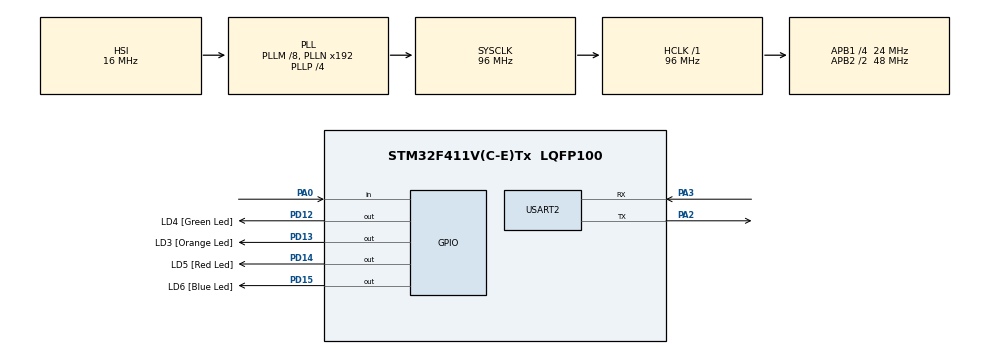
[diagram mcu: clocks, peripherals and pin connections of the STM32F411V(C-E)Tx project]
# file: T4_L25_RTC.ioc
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Mcu.Family=STM32F4
Mcu.Name=STM32F411V(C-E)Tx
Mcu.Package=LQFP100
NVIC.PriorityGroup=NVIC_PRIORITYGROUP_0
PA0-WKUP.Signal=GPIO_Input
PA2.Mode=Asynchronous
PA2.Signal=USART2_TX
PA3.Mode=Asynchronous
PA3.Signal=USART2_RX
PC14-OSC32_IN.Mode=LSE-External-Oscillator
PC14-OSC32_IN.Signal=RCC_OSC32_IN
PC15-OSC32_OUT.Mode=LSE-External-Oscillator
PC15-OSC32_OUT.Signal=RCC_OSC32_OUT
PD12.GPIO_Label=LD4 [Green Led]
PD12.GPIO_PuPd=GPIO_NOPULL
PD12.GPIO_Speed=GPIO_SPEED_FREQ_LOW
PD12.Signal=GPIO_Output
PD13.GPIO_Label=LD3 [Orange Led]
PD13.GPIO_PuPd=GPIO_NOPULL
PD13.GPIO_Speed=GPIO_SPEED_FREQ_LOW
PD13.Signal=GPIO_Output
PD14.GPIO_Label=LD5 [Red Led]
PD14.GPIO_PuPd=GPIO_NOPULL
PD14.GPIO_Speed=GPIO_SPEED_FREQ_LOW
PD14.Signal=GPIO_Output
PD15.GPIO_Label=LD6 [Blue Led]
PD15.GPIO_PuPd=GPIO_NOPULL
PD15.GPIO_Speed=GPIO_SPEED_FREQ_LOW
PD15.Signal=GPIO_Output
ProjectManager.HeapSize=0x200
ProjectManager.StackSize=0x400
ProjectManager.TargetToolchain=STM32CubeIDE
RCC.48MHZClocksFreq_Value=48000000
RCC.AHBFreq_Value=96000000
RCC.APB1CLKDivider=RCC_HCLK_DIV4
RCC.APB1Freq_Value=24000000
RCC.APB1TimFreq_Value=48000000
RCC.APB2CLKDivider=RCC_HCLK_DIV2
RCC.APB2Freq_Value=48000000
RCC.APB2TimFreq_Value=96000000
RCC.CortexFreq_Value=96000000
RCC.HCLKFreq_Value=96000000
RCC.HSE_VALUE=8000000
RCC.HSI_VALUE=16000000
RCC.PLLI2SM=5
RCC.PLLI2SN=200
RCC.PLLM=8
RCC.PLLP=RCC_PLLP_DIV4
RCC.PLLQ=8
RCC.RCC_RTC_Clock_Source=RCC_RTCCLKSOURCE_LSE
RCC.SYSCLKFreq_VALUE=96000000
RCC.SYSCLKSource=RCC_SYSCLKSOURCE_PLLCLK
RCC.VCOOutputFreq_Value=384000000
RTC.Date=9
RTC.Hours=22
RTC.Minutes=33
RTC.Month=RTC_MONTH_MARCH
RTC.Seconds=11
RTC.WeekDay=RTC_WEEKDAY_THURSDAY
RTC.Year=44
USART2.VirtualMode=VM_ASYNC
VP_RTC_VS_RTC_Activate.Mode=RTC_Enabled
VP_RTC_VS_RTC_Calendar.Mode=RTC_Calendar
board=STM32F411E-DISCO

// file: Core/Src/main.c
/* USER CODE BEGIN Header */
/**
  ******************************************************************************
  * @file           : main.c
  * @brief          : Main program body
  ******************************************************************************
  * @attention
  *
  * <h2><center>&copy; Copyright (c) 2021 STMicroelectronics.
  * All rights reserved.</center></h2>
  *
  * This software component is licensed by ST under BSD 3-Clause license,
  * the "License"; You may not use this file except in compliance with the
  * License. You may obtain a copy of the License at:
  *                        opensource.org/licenses/BSD-3-Clause
  *
  ******************************************************************************
  */
/* USER CODE END Header */
#include "main.h"
#include "rtc.h"
#include "usart.h"
#include "gpio.h"

/* USER CODE BEGIN Includes */
#include  <stdio.h>
/* USER CODE END Includes */

/* USER CODE BEGIN PV */
RTC_TimeTypeDef RtcTime;
RTC_DateTypeDef RtcDate;

uint8_t CompareSeconds;
float Milliseconds;

uint8_t Message[64];
uint8_t MessageLen;

/* USER CODE END PV */

void SystemClock_Config(void);

int main(void)
{

  /* MCU Configuration--------------------------------------------------------*/

  /* Reset of all peripherals, Initializes the Flash interface and the Systick. */
  HAL_Init();

  /* Configure the system clock */
  SystemClock_Config();

  /* Initialize all configured peripherals */
  MX_GPIO_Init();
  MX_USART2_UART_Init();
  MX_RTC_Init();

  /* Infinite loop */
  /* USER CODE BEGIN WHILE */
  while (1)
  {
	  HAL_RTC_GetTime(&hrtc, &RtcTime, RTC_FORMAT_BIN);
	  HAL_RTC_GetDate(&hrtc, &RtcDate, RTC_FORMAT_BIN);

	  MessageLen = sprintf((char*)Message, "Date: %02d.%02d.20%02d Time:%02d:%02d:%02d:\n\r", RtcDate.Date, RtcDate.Month,RtcDate.Year, RtcTime.Hours, RtcTime.Minutes, RtcTime.Seconds);
	  HAL_UART_Transmit(&huart2, Message, MessageLen, 100);
    /* USER CODE END WHILE */

  }
}

void SystemClock_Config(void)
{
  RCC_OscInitTypeDef RCC_OscInitStruct = {0};
  RCC_ClkInitTypeDef RCC_ClkInitStruct = {0};
  RCC_PeriphCLKInitTypeDef PeriphClkInitStruct = {0};

  /** Configure the main internal regulator output voltage
  */
  __HAL_RCC_PWR_CLK_ENABLE();
  __HAL_PWR_VOLTAGESCALING_CONFIG(PWR_REGULATOR_VOLTAGE_SCALE1);
  /** Initializes the RCC Oscillators according to the specified parameters
  * in the RCC_OscInitTypeDef structure.
  */
  RCC_OscInitStruct.OscillatorType = RCC_OSCILLATORTYPE_HSI|RCC_OSCILLATORTYPE_LSE;
  RCC_OscInitStruct.LSEState = RCC_LSE_ON;
  RCC_OscInitStruct.HSIState = RCC_HSI_ON;
  RCC_OscInitStruct.HSICalibrationValue = RCC_HSICALIBRATION_DEFAULT;
  RCC_OscInitStruct.PLL.PLLState = RCC_PLL_ON;
  RCC_OscInitStruct.PLL.PLLSource = RCC_PLLSOURCE_HSI;
  RCC_OscInitStruct.PLL.PLLM = 8;
  RCC_OscInitStruct.PLL.PLLN = 192;
  RCC_OscInitStruct.PLL.PLLP = RCC_PLLP_DIV4;
  RCC_OscInitStruct.PLL.PLLQ = 8;
  if (HAL_RCC_OscConfig(&RCC_OscInitStruct) != HAL_OK)
  {
    Error_Handler();
  }
  /** Initializes the CPU, AHB and APB buses clocks
  */
  RCC_ClkInitStruct.ClockType = RCC_CLOCKTYPE_HCLK|RCC_CLOCKTYPE_SYSCLK
                              |RCC_CLOCKTYPE_PCLK1|RCC_CLOCKTYPE_PCLK2;
  RCC_ClkInitStruct.SYSCLKSource = RCC_SYSCLKSOURCE_PLLCLK;
  RCC_ClkInitStruct.AHBCLKDivider = RCC_SYSCLK_DIV1;
  RCC_ClkInitStruct.APB1CLKDivider = RCC_HCLK_DIV4;
  RCC_ClkInitStruct.APB2CLKDivider = RCC_HCLK_DIV2;

  if (HAL_RCC_ClockConfig(&RCC_ClkInitStruct, FLASH_LATENCY_3) != HAL_OK)
  {
    Error_Handler();
  }
  PeriphClkInitStruct.PeriphClockSelection = RCC_PERIPHCLK_RTC;
  PeriphClkInitStruct.RTCClockSelection = RCC_RTCCLKSOURCE_LSE;
  if (HAL_RCCEx_PeriphCLKConfig(&PeriphClkInitStruct) != HAL_OK)
  {
    Error_Handler();
  }
}

void Error_Handler(void)
{
}

/************************ (C) COPYRIGHT STMicroelectronics *****END OF FILE****/
